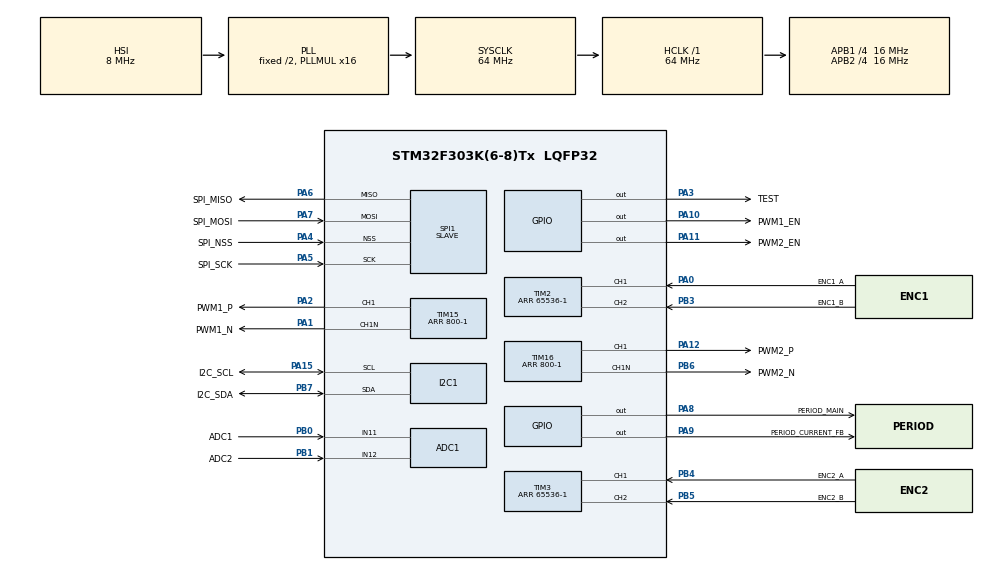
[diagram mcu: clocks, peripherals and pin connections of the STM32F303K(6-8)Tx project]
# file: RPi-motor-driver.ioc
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ADC1.Channel-1\#ChannelRegularConversion=ADC_CHANNEL_11
ADC1.Channel-2\#ChannelRegularConversion=ADC_CHANNEL_12
ADC1.ClockPrescaler=ADC_CLOCK_SYNC_PCLK_DIV4
ADC1.ContinuousConvMode=ENABLE
ADC1.DMAContinuousRequests=ENABLE
ADC1.EOCSelection=ADC_EOC_SINGLE_CONV
ADC1.EnableInjectedConversion=DISABLE
ADC1.NbrOfConversion=2
ADC1.NbrOfConversionFlag=1
ADC1.Offset-1\#ChannelRegularConversion=0
ADC1.Offset-2\#ChannelRegularConversion=0
ADC1.OffsetNumber-1\#ChannelRegularConversion=ADC_OFFSET_NONE
ADC1.OffsetNumber-2\#ChannelRegularConversion=ADC_OFFSET_NONE
ADC1.Rank-1\#ChannelRegularConversion=1
ADC1.Rank-2\#ChannelRegularConversion=2
ADC1.SamplingTime-1\#ChannelRegularConversion=ADC_SAMPLETIME_181CYCLES_5
ADC1.SamplingTime-2\#ChannelRegularConversion=ADC_SAMPLETIME_181CYCLES_5
ADC1.SequencerNbRanks=1
ADC1.SubFamily=STM32F303x8
ADC1.master=1
Dma.ADC1.0.Direction=DMA_PERIPH_TO_MEMORY
Dma.ADC1.0.Instance=DMA1_Channel1
Dma.ADC1.0.MemDataAlignment=DMA_MDATAALIGN_HALFWORD
Dma.ADC1.0.MemInc=DMA_MINC_ENABLE
Dma.ADC1.0.Mode=DMA_CIRCULAR
Dma.ADC1.0.PeriphDataAlignment=DMA_PDATAALIGN_HALFWORD
Dma.ADC1.0.PeriphInc=DMA_PINC_DISABLE
Dma.ADC1.0.Priority=DMA_PRIORITY_LOW
Dma.Request0=ADC1
Mcu.Family=STM32F3
Mcu.Name=STM32F303K(6-8)Tx
Mcu.Package=LQFP32
NVIC.DMA1_Channel1_IRQn=true\:0\:0\:false\:false\:true\:false\:true\:true
NVIC.PriorityGroup=NVIC_PRIORITYGROUP_4
NVIC.SPI1_IRQn=true\:0\:0\:false\:false\:true\:true\:true\:true
NVIC.TIM1_TRG_COM_TIM17_IRQn=true\:0\:0\:false\:false\:true\:true\:true\:true
NVIC.TIM1_UP_TIM16_IRQn=true\:15\:0\:false\:false\:true\:false\:true\:true
NVIC.TIM2_IRQn=true\:0\:0\:false\:false\:true\:true\:true\:true
NVIC.TIM3_IRQn=true\:0\:0\:false\:false\:true\:true\:true\:true
NVIC.TIM6_DAC1_IRQn=true\:0\:0\:false\:false\:true\:true\:true\:true
PA0.GPIO_Label=ENC1_A
PA0.Signal=S_TIM2_CH1_ETR
PA1.GPIO_Label=PWM1_N
PA1.Mode=PWM Generation1 CH1 CH1N
PA1.Signal=TIM15_CH1N
PA10.GPIO_Label=PWM1_EN
PA10.GPIO_PuPd=GPIO_PULLDOWN
PA10.Signal=GPIO_Output
PA11.GPIO_Label=PWM2_EN
PA11.GPIO_PuPd=GPIO_PULLDOWN
PA11.Signal=GPIO_Output
PA12.GPIO_Label=PWM2_P
PA12.Signal=S_TIM16_CH1
PA13.GPIO_Label=SWDIO
PA13.Mode=Serial_Wire
PA13.Signal=SYS_JTMS-SWDIO
PA14.GPIO_Label=SWCLK
PA14.Mode=Serial_Wire
PA14.Signal=SYS_JTCK-SWCLK
PA15.GPIO_Label=I2C_SCL
PA15.Mode=I2C
PA15.Signal=I2C1_SCL
PA2.GPIO_Label=PWM1_P
PA2.Signal=S_TIM15_CH1
PA3.GPIO_Label=TEST
PA3.GPIO_PuPd=GPIO_PULLUP
PA3.PinState=GPIO_PIN_RESET
PA3.Signal=GPIO_Output
PA4.GPIO_Label=SPI_NSS
PA4.GPIO_PuPd=GPIO_NOPULL
PA4.Mode=NSS_Signal_Hard_Input
PA4.Signal=SPI1_NSS
PA5.GPIO_Label=SPI_SCK
PA5.GPIO_PuPd=GPIO_NOPULL
PA5.Mode=Full_Duplex_Slave
PA5.Signal=SPI1_SCK
PA6.GPIO_Label=SPI_MISO
PA6.GPIO_PuPd=GPIO_NOPULL
PA6.Mode=Full_Duplex_Slave
PA6.Signal=SPI1_MISO
PA7.GPIO_Label=SPI_MOSI
PA7.GPIO_PuPd=GPIO_NOPULL
PA7.Mode=Full_Duplex_Slave
PA7.Signal=SPI1_MOSI
PA8.GPIO_Label=PERIOD_MAIN
PA8.GPIO_PuPd=GPIO_PULLUP
PA8.Signal=GPIO_Output
PA9.GPIO_Label=PERIOD_CURRENT_FB
PA9.GPIO_PuPd=GPIO_PULLUP
PA9.Signal=GPIO_Output
PB0.GPIO_Label=ADC1
PB0.Mode=IN11-Single-Ended
PB0.Signal=ADC1_IN11
PB1.GPIO_Label=ADC2
PB1.Mode=IN12-Single-Ended
PB1.Signal=ADC1_IN12
PB3.GPIO_Label=ENC1_B
PB3.Signal=S_TIM2_CH2
PB4.GPIO_Label=ENC2_A
PB4.Signal=S_TIM3_CH1
PB5.GPIO_Label=ENC2_B
PB5.Signal=S_TIM3_CH2
PB6.GPIO_Label=PWM2_N
PB6.Mode=PWM Generation1 CH1 CH1N
PB6.Signal=TIM16_CH1N
PB7.GPIO_Label=I2C_SDA
PB7.Mode=I2C
PB7.Signal=I2C1_SDA
ProjectManager.HeapSize=0x200
ProjectManager.StackSize=0x400
ProjectManager.TargetToolchain=STM32CubeIDE
RCC.AHBFreq_Value=64000000
RCC.APB1CLKDivider=RCC_HCLK_DIV4
RCC.APB1Freq_Value=16000000
RCC.APB1TimFreq_Value=32000000
RCC.APB2CLKDivider=RCC_HCLK_DIV4
RCC.APB2Freq_Value=16000000
RCC.APB2TimFreq_Value=32000000
RCC.CortexFreq_Value=8000000
RCC.Cortex_Div=SYSTICK_CLKSOURCE_HCLK_DIV8
RCC.HCLKFreq_Value=64000000
RCC.HSE_VALUE=8000000
RCC.HSI_VALUE=8000000
RCC.PLLMUL=RCC_PLL_MUL16
RCC.SYSCLKFreq_VALUE=64000000
RCC.SYSCLKSourceVirtual=RCC_SYSCLKSOURCE_PLLCLK
SH.S_TIM15_CH1.0=TIM15_CH1,PWM Generation1 CH1 CH1N
SH.S_TIM16_CH1.0=TIM16_CH1,PWM Generation1 CH1 CH1N
SH.S_TIM2_CH1_ETR.0=TIM2_CH1,Encoder_Interface
SH.S_TIM2_CH2.0=TIM2_CH2,Encoder_Interface
SH.S_TIM3_CH1.0=TIM3_CH1,Encoder_Interface
SH.S_TIM3_CH2.0=TIM3_CH2,Encoder_Interface
SPI1.DataSize=SPI_DATASIZE_8BIT
SPI1.Direction=SPI_DIRECTION_2LINES
SPI1.Mode=SPI_MODE_SLAVE
SPI1.VirtualNSS=VM_NSSHARD
SPI1.VirtualType=VM_SLAVE
TIM15.Channel-PWM\ Generation1\ CH1\ CH1N=TIM_CHANNEL_1
TIM15.DeadTime=0
TIM15.Period=800-1
TIM15.Pulse-PWM\ Generation1\ CH1\ CH1N=400
TIM16.Channel=TIM_CHANNEL_1
TIM16.ClockDivision=TIM_CLOCKDIVISION_DIV1
TIM16.Period=800-1
TIM16.Pulse=400
TIM17.Period=3200-1
TIM2.EncoderMode=TIM_ENCODERMODE_TI12
TIM2.Period=65536-1
TIM3.EncoderMode=TIM_ENCODERMODE_TI12
TIM3.Period=65536-1
TIM6.Period=32000-1
TIM6.Prescaler=0
VP_TIM16_VS_ClockSourceINT.Mode=Enable_Timer
VP_TIM17_VS_ClockSourceINT.Mode=Enable_Timer
VP_TIM6_VS_ClockSourceINT.Mode=Enable_Timer
board=custom

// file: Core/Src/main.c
/* USER CODE BEGIN Header */
/**
 ******************************************************************************
 * @file           : main.c
 * @brief          : Main program body
 ******************************************************************************
 * @attention
 *
 * Copyright (c) 2023 STMicroelectronics.
 * All rights reserved.
 *
 * This software is licensed under terms that can be found in the LICENSE file
 * in the root directory of this software component.
 * If no LICENSE file comes with this software, it is provided AS-IS.
 *
 ******************************************************************************
 */
/* USER CODE END Header */
#include "main.h"

/* USER CODE BEGIN Includes */
#include "board.h"
#include "callback.h"
/* USER CODE END Includes */

ADC_HandleTypeDef hadc1;
DMA_HandleTypeDef hdma_adc1;

I2C_HandleTypeDef hi2c1;

SPI_HandleTypeDef hspi1;

TIM_HandleTypeDef htim2;
TIM_HandleTypeDef htim3;
TIM_HandleTypeDef htim6;
TIM_HandleTypeDef htim15;
TIM_HandleTypeDef htim16;
TIM_HandleTypeDef htim17;

void SystemClock_Config(void);
static void MX_GPIO_Init(void);
static void MX_DMA_Init(void);
static void MX_ADC1_Init(void);
static void MX_I2C1_Init(void);
static void MX_SPI1_Init(void);
static void MX_TIM2_Init(void);
static void MX_TIM3_Init(void);
static void MX_TIM15_Init(void);
static void MX_TIM16_Init(void);
static void MX_TIM17_Init(void);
static void MX_TIM6_Init(void);

int main(void)
{

  /* MCU Configuration--------------------------------------------------------*/

  /* Reset of all peripherals, Initializes the Flash interface and the Systick. */
  HAL_Init();

  /* Configure the system clock */
  SystemClock_Config();

  /* Initialize all configured peripherals */
  MX_GPIO_Init();
  MX_DMA_Init();
  MX_ADC1_Init();
  MX_I2C1_Init();
  MX_SPI1_Init();
  MX_TIM2_Init();
  MX_TIM3_Init();
  MX_TIM15_Init();
  MX_TIM16_Init();
  MX_TIM17_Init();
  MX_TIM6_Init();
  /* USER CODE BEGIN 2 */
	/* State initialize */
	board_start();
  /* USER CODE END 2 */

  /* Infinite loop */
  /* USER CODE BEGIN WHILE */
	while (1) {
		/* Check main process execution period START */
		HAL_GPIO_WritePin(PERIOD_MAIN_GPIO_Port, PERIOD_MAIN_Pin, GPIO_PIN_SET);

		/* Updating state */
		board_update();

		/* Check main process execution period END */
		HAL_GPIO_WritePin(PERIOD_MAIN_GPIO_Port, PERIOD_MAIN_Pin,
				GPIO_PIN_RESET);
    /* USER CODE END WHILE */

	}
}

void SystemClock_Config(void)
{
  RCC_OscInitTypeDef RCC_OscInitStruct = {0};
  RCC_ClkInitTypeDef RCC_ClkInitStruct = {0};
  RCC_PeriphCLKInitTypeDef PeriphClkInit = {0};

  /** Initializes the RCC Oscillators according to the specified parameters
  * in the RCC_OscInitTypeDef structure.
  */
  RCC_OscInitStruct.OscillatorType = RCC_OSCILLATORTYPE_HSI;
  RCC_OscInitStruct.HSIState = RCC_HSI_ON;
  RCC_OscInitStruct.HSICalibrationValue = RCC_HSICALIBRATION_DEFAULT;
  RCC_OscInitStruct.PLL.PLLState = RCC_PLL_ON;
  RCC_OscInitStruct.PLL.PLLSource = RCC_PLLSOURCE_HSI;
  RCC_OscInitStruct.PLL.PLLMUL = RCC_PLL_MUL16;
  if (HAL_RCC_OscConfig(&RCC_OscInitStruct) != HAL_OK)
  {
    Error_Handler();
  }

  /** Initializes the CPU, AHB and APB buses clocks
  */
  RCC_ClkInitStruct.ClockType = RCC_CLOCKTYPE_HCLK|RCC_CLOCKTYPE_SYSCLK
                              |RCC_CLOCKTYPE_PCLK1|RCC_CLOCKTYPE_PCLK2;
  RCC_ClkInitStruct.SYSCLKSource = RCC_SYSCLKSOURCE_PLLCLK;
  RCC_ClkInitStruct.AHBCLKDivider = RCC_SYSCLK_DIV1;
  RCC_ClkInitStruct.APB1CLKDivider = RCC_HCLK_DIV4;
  RCC_ClkInitStruct.APB2CLKDivider = RCC_HCLK_DIV4;

  if (HAL_RCC_ClockConfig(&RCC_ClkInitStruct, FLASH_LATENCY_2) != HAL_OK)
  {
    Error_Handler();
  }
  PeriphClkInit.PeriphClockSelection = RCC_PERIPHCLK_I2C1;
  PeriphClkInit.I2c1ClockSelection = RCC_I2C1CLKSOURCE_HSI;
  if (HAL_RCCEx_PeriphCLKConfig(&PeriphClkInit) != HAL_OK)
  {
    Error_Handler();
  }
}

static void MX_ADC1_Init(void)
{

  ADC_MultiModeTypeDef multimode = {0};
  ADC_ChannelConfTypeDef sConfig = {0};

  /** Common config
  */
  hadc1.Instance = ADC1;
  hadc1.Init.ClockPrescaler = ADC_CLOCK_SYNC_PCLK_DIV4;
  hadc1.Init.Resolution = ADC_RESOLUTION_12B;
  hadc1.Init.ScanConvMode = ADC_SCAN_ENABLE;
  hadc1.Init.ContinuousConvMode = ENABLE;
  hadc1.Init.DiscontinuousConvMode = DISABLE;
  hadc1.Init.ExternalTrigConvEdge = ADC_EXTERNALTRIGCONVEDGE_NONE;
  hadc1.Init.ExternalTrigConv = ADC_SOFTWARE_START;
  hadc1.Init.DataAlign = ADC_DATAALIGN_RIGHT;
  hadc1.Init.NbrOfConversion = 2;
  hadc1.Init.DMAContinuousRequests = ENABLE;
  hadc1.Init.EOCSelection = ADC_EOC_SINGLE_CONV;
  hadc1.Init.LowPowerAutoWait = DISABLE;
  hadc1.Init.Overrun = ADC_OVR_DATA_OVERWRITTEN;
  if (HAL_ADC_Init(&hadc1) != HAL_OK)
  {
    Error_Handler();
  }

  /** Configure the ADC multi-mode
  */
  multimode.Mode = ADC_MODE_INDEPENDENT;
  if (HAL_ADCEx_MultiModeConfigChannel(&hadc1, &multimode) != HAL_OK)
  {
    Error_Handler();
  }

  /** Configure Regular Channel
  */
  sConfig.Channel = ADC_CHANNEL_11;
  sConfig.Rank = ADC_REGULAR_RANK_1;
  sConfig.SingleDiff = ADC_SINGLE_ENDED;
  sConfig.SamplingTime = ADC_SAMPLETIME_181CYCLES_5;
  sConfig.OffsetNumber = ADC_OFFSET_NONE;
  sConfig.Offset = 0;
  if (HAL_ADC_ConfigChannel(&hadc1, &sConfig) != HAL_OK)
  {
    Error_Handler();
  }

  /** Configure Regular Channel
  */
  sConfig.Channel = ADC_CHANNEL_12;
  sConfig.Rank = ADC_REGULAR_RANK_2;
  if (HAL_ADC_ConfigChannel(&hadc1, &sConfig) != HAL_OK)
  {
    Error_Handler();
  }

}

static void MX_I2C1_Init(void)
{

  hi2c1.Instance = I2C1;
  hi2c1.Init.Timing = 0x2000090E;
  hi2c1.Init.OwnAddress1 = 0;
  hi2c1.Init.AddressingMode = I2C_ADDRESSINGMODE_7BIT;
  hi2c1.Init.DualAddressMode = I2C_DUALADDRESS_DISABLE;
  hi2c1.Init.OwnAddress2 = 0;
  hi2c1.Init.OwnAddress2Masks = I2C_OA2_NOMASK;
  hi2c1.Init.GeneralCallMode = I2C_GENERALCALL_DISABLE;
  hi2c1.Init.NoStretchMode = I2C_NOSTRETCH_DISABLE;
  if (HAL_I2C_Init(&hi2c1) != HAL_OK)
  {
    Error_Handler();
  }

  /** Configure Analogue filter
  */
  if (HAL_I2CEx_ConfigAnalogFilter(&hi2c1, I2C_ANALOGFILTER_ENABLE) != HAL_OK)
  {
    Error_Handler();
  }

  /** Configure Digital filter
  */
  if (HAL_I2CEx_ConfigDigitalFilter(&hi2c1, 0) != HAL_OK)
  {
    Error_Handler();
  }

}

static void MX_SPI1_Init(void)
{

  /* SPI1 parameter configuration*/
  hspi1.Instance = SPI1;
  hspi1.Init.Mode = SPI_MODE_SLAVE;
  hspi1.Init.Direction = SPI_DIRECTION_2LINES;
  hspi1.Init.DataSize = SPI_DATASIZE_8BIT;
  hspi1.Init.CLKPolarity = SPI_POLARITY_LOW;
  hspi1.Init.CLKPhase = SPI_PHASE_1EDGE;
  hspi1.Init.NSS = SPI_NSS_HARD_INPUT;
  hspi1.Init.FirstBit = SPI_FIRSTBIT_MSB;
  hspi1.Init.TIMode = SPI_TIMODE_DISABLE;
  hspi1.Init.CRCCalculation = SPI_CRCCALCULATION_DISABLE;
  hspi1.Init.CRCPolynomial = 7;
  hspi1.Init.CRCLength = SPI_CRC_LENGTH_DATASIZE;
  hspi1.Init.NSSPMode = SPI_NSS_PULSE_DISABLE;
  if (HAL_SPI_Init(&hspi1) != HAL_OK)
  {
    Error_Handler();
  }

}

static void MX_TIM2_Init(void)
{

  TIM_Encoder_InitTypeDef sConfig = {0};
  TIM_MasterConfigTypeDef sMasterConfig = {0};

  htim2.Instance = TIM2;
  htim2.Init.Prescaler = 0;
  htim2.Init.CounterMode = TIM_COUNTERMODE_UP;
  htim2.Init.Period = 65536-1;
  htim2.Init.ClockDivision = TIM_CLOCKDIVISION_DIV1;
  htim2.Init.AutoReloadPreload = TIM_AUTORELOAD_PRELOAD_DISABLE;
  sConfig.EncoderMode = TIM_ENCODERMODE_TI12;
  sConfig.IC1Polarity = TIM_ICPOLARITY_RISING;
  sConfig.IC1Selection = TIM_ICSELECTION_DIRECTTI;
  sConfig.IC1Prescaler = TIM_ICPSC_DIV1;
  sConfig.IC1Filter = 0;
  sConfig.IC2Polarity = TIM_ICPOLARITY_RISING;
  sConfig.IC2Selection = TIM_ICSELECTION_DIRECTTI;
  sConfig.IC2Prescaler = TIM_ICPSC_DIV1;
  sConfig.IC2Filter = 0;
  if (HAL_TIM_Encoder_Init(&htim2, &sConfig) != HAL_OK)
  {
    Error_Handler();
  }
  sMasterConfig.MasterOutputTrigger = TIM_TRGO_RESET;
  sMasterConfig.MasterSlaveMode = TIM_MASTERSLAVEMODE_DISABLE;
  if (HAL_TIMEx_MasterConfigSynchronization(&htim2, &sMasterConfig) != HAL_OK)
  {
    Error_Handler();
  }

}

static void MX_TIM3_Init(void)
{

  TIM_Encoder_InitTypeDef sConfig = {0};
  TIM_MasterConfigTypeDef sMasterConfig = {0};

  htim3.Instance = TIM3;
  htim3.Init.Prescaler = 0;
  htim3.Init.CounterMode = TIM_COUNTERMODE_UP;
  htim3.Init.Period = 65536-1;
  htim3.Init.ClockDivision = TIM_CLOCKDIVISION_DIV1;
  htim3.Init.AutoReloadPreload = TIM_AUTORELOAD_PRELOAD_DISABLE;
  sConfig.EncoderMode = TIM_ENCODERMODE_TI12;
  sConfig.IC1Polarity = TIM_ICPOLARITY_RISING;
  sConfig.IC1Selection = TIM_ICSELECTION_DIRECTTI;
  sConfig.IC1Prescaler = TIM_ICPSC_DIV1;
  sConfig.IC1Filter = 0;
  sConfig.IC2Polarity = TIM_ICPOLARITY_RISING;
  sConfig.IC2Selection = TIM_ICSELECTION_DIRECTTI;
  sConfig.IC2Prescaler = TIM_ICPSC_DIV1;
  sConfig.IC2Filter = 0;
  if (HAL_TIM_Encoder_Init(&htim3, &sConfig) != HAL_OK)
  {
    Error_Handler();
  }
  sMasterConfig.MasterOutputTrigger = TIM_TRGO_RESET;
  sMasterConfig.MasterSlaveMode = TIM_MASTERSLAVEMODE_DISABLE;
  if (HAL_TIMEx_MasterConfigSynchronization(&htim3, &sMasterConfig) != HAL_OK)
  {
    Error_Handler();
  }

}

static void MX_TIM6_Init(void)
{

  TIM_MasterConfigTypeDef sMasterConfig = {0};

  htim6.Instance = TIM6;
  htim6.Init.Prescaler = 0;
  htim6.Init.CounterMode = TIM_COUNTERMODE_UP;
  htim6.Init.Period = 32000-1;
  htim6.Init.AutoReloadPreload = TIM_AUTORELOAD_PRELOAD_DISABLE;
  if (HAL_TIM_Base_Init(&htim6) != HAL_OK)
  {
    Error_Handler();
  }
  sMasterConfig.MasterOutputTrigger = TIM_TRGO_RESET;
  sMasterConfig.MasterSlaveMode = TIM_MASTERSLAVEMODE_DISABLE;
  if (HAL_TIMEx_MasterConfigSynchronization(&htim6, &sMasterConfig) != HAL_OK)
  {
    Error_Handler();
  }

}

static void MX_TIM15_Init(void)
{

  TIM_MasterConfigTypeDef sMasterConfig = {0};
  TIM_OC_InitTypeDef sConfigOC = {0};
  TIM_BreakDeadTimeConfigTypeDef sBreakDeadTimeConfig = {0};

  htim15.Instance = TIM15;
  htim15.Init.Prescaler = 0;
  htim15.Init.CounterMode = TIM_COUNTERMODE_UP;
  htim15.Init.Period = 800-1;
  htim15.Init.ClockDivision = TIM_CLOCKDIVISION_DIV1;
  htim15.Init.RepetitionCounter = 0;
  htim15.Init.AutoReloadPreload = TIM_AUTORELOAD_PRELOAD_DISABLE;
  if (HAL_TIM_PWM_Init(&htim15) != HAL_OK)
  {
    Error_Handler();
  }
  sMasterConfig.MasterOutputTrigger = TIM_TRGO_RESET;
  sMasterConfig.MasterSlaveMode = TIM_MASTERSLAVEMODE_DISABLE;
  if (HAL_TIMEx_MasterConfigSynchronization(&htim15, &sMasterConfig) != HAL_OK)
  {
    Error_Handler();
  }
  sConfigOC.OCMode = TIM_OCMODE_PWM1;
  sConfigOC.Pulse = 400;
  sConfigOC.OCPolarity = TIM_OCPOLARITY_HIGH;
  sConfigOC.OCNPolarity = TIM_OCNPOLARITY_HIGH;
  sConfigOC.OCFastMode = TIM_OCFAST_DISABLE;
  sConfigOC.OCIdleState = TIM_OCIDLESTATE_RESET;
  sConfigOC.OCNIdleState = TIM_OCNIDLESTATE_RESET;
  if (HAL_TIM_PWM_ConfigChannel(&htim15, &sConfigOC, TIM_CHANNEL_1) != HAL_OK)
  {
    Error_Handler();
  }
  sBreakDeadTimeConfig.OffStateRunMode = TIM_OSSR_DISABLE;
  sBreakDeadTimeConfig.OffStateIDLEMode = TIM_OSSI_DISABLE;
  sBreakDeadTimeConfig.LockLevel = TIM_LOCKLEVEL_OFF;
  sBreakDeadTimeConfig.DeadTime = 0;
  sBreakDeadTimeConfig.BreakState = TIM_BREAK_DISABLE;
  sBreakDeadTimeConfig.BreakPolarity = TIM_BREAKPOLARITY_HIGH;
  sBreakDeadTimeConfig.BreakFilter = 0;
  sBreakDeadTimeConfig.AutomaticOutput = TIM_AUTOMATICOUTPUT_DISABLE;
  if (HAL_TIMEx_ConfigBreakDeadTime(&htim15, &sBreakDeadTimeConfig) != HAL_OK)
  {
    Error_Handler();
  }
  HAL_TIM_MspPostInit(&htim15);

}

static void MX_TIM16_Init(void)
{

  TIM_OC_InitTypeDef sConfigOC = {0};
  TIM_BreakDeadTimeConfigTypeDef sBreakDeadTimeConfig = {0};

  htim16.Instance = TIM16;
  htim16.Init.Prescaler = 0;
  htim16.Init.CounterMode = TIM_COUNTERMODE_UP;
  htim16.Init.Period = 800-1;
  htim16.Init.ClockDivision = TIM_CLOCKDIVISION_DIV1;
  htim16.Init.RepetitionCounter = 0;
  htim16.Init.AutoReloadPreload = TIM_AUTORELOAD_PRELOAD_DISABLE;
  if (HAL_TIM_Base_Init(&htim16) != HAL_OK)
  {
    Error_Handler();
  }
  if (HAL_TIM_PWM_Init(&htim16) != HAL_OK)
  {
    Error_Handler();
  }
  sConfigOC.OCMode = TIM_OCMODE_PWM1;
  sConfigOC.Pulse = 400;
  sConfigOC.OCPolarity = TIM_OCPOLARITY_HIGH;
  sConfigOC.OCNPolarity = TIM_OCNPOLARITY_HIGH;
  sConfigOC.OCFastMode = TIM_OCFAST_DISABLE;
  sConfigOC.OCIdleState = TIM_OCIDLESTATE_RESET;
  sConfigOC.OCNIdleState = TIM_OCNIDLESTATE_RESET;
  if (HAL_TIM_PWM_ConfigChannel(&htim16, &sConfigOC, TIM_CHANNEL_1) != HAL_OK)
  {
    Error_Handler();
  }
  sBreakDeadTimeConfig.OffStateRunMode = TIM_OSSR_DISABLE;
  sBreakDeadTimeConfig.OffStateIDLEMode = TIM_OSSI_DISABLE;
  sBreakDeadTimeConfig.LockLevel = TIM_LOCKLEVEL_OFF;
  sBreakDeadTimeConfig.DeadTime = 0;
  sBreakDeadTimeConfig.BreakState = TIM_BREAK_DISABLE;
  sBreakDeadTimeConfig.BreakPolarity = TIM_BREAKPOLARITY_HIGH;
  sBreakDeadTimeConfig.BreakFilter = 0;
  sBreakDeadTimeConfig.AutomaticOutput = TIM_AUTOMATICOUTPUT_DISABLE;
  if (HAL_TIMEx_ConfigBreakDeadTime(&htim16, &sBreakDeadTimeConfig) != HAL_OK)
  {
    Error_Handler();
  }
  HAL_TIM_MspPostInit(&htim16);

}

static void MX_TIM17_Init(void)
{

  htim17.Instance = TIM17;
  htim17.Init.Prescaler = 0;
  htim17.Init.CounterMode = TIM_COUNTERMODE_UP;
  htim17.Init.Period = 3200-1;
  htim17.Init.ClockDivision = TIM_CLOCKDIVISION_DIV1;
  htim17.Init.RepetitionCounter = 0;
  htim17.Init.AutoReloadPreload = TIM_AUTORELOAD_PRELOAD_DISABLE;
  if (HAL_TIM_Base_Init(&htim17) != HAL_OK)
  {
    Error_Handler();
  }

}

static void MX_DMA_Init(void)
{

  /* DMA controller clock enable */
  __HAL_RCC_DMA1_CLK_ENABLE();

  /* DMA interrupt init */
  /* DMA1_Channel1_IRQn interrupt configuration */
  HAL_NVIC_SetPriority(DMA1_Channel1_IRQn, 0, 0);
  HAL_NVIC_EnableIRQ(DMA1_Channel1_IRQn);

}

static void MX_GPIO_Init(void)
{
  GPIO_InitTypeDef GPIO_InitStruct = {0};

  /* GPIO Ports Clock Enable */
  __HAL_RCC_GPIOA_CLK_ENABLE();
  __HAL_RCC_GPIOB_CLK_ENABLE();

  /*Configure GPIO pin Output Level */
  HAL_GPIO_WritePin(GPIOA, TEST_Pin|PERIOD_MAIN_Pin|PERIOD_CURRENT_FB_Pin|PWM1_EN_Pin
                          |PWM2_EN_Pin, GPIO_PIN_RESET);

  /*Configure GPIO pins : TEST_Pin PERIOD_MAIN_Pin PERIOD_CURRENT_FB_Pin */
  GPIO_InitStruct.Pin = TEST_Pin|PERIOD_MAIN_Pin|PERIOD_CURRENT_FB_Pin;
  GPIO_InitStruct.Mode = GPIO_MODE_OUTPUT_PP;
  GPIO_InitStruct.Pull = GPIO_PULLUP;
  GPIO_InitStruct.Speed = GPIO_SPEED_FREQ_LOW;
  HAL_GPIO_Init(GPIOA, &GPIO_InitStruct);

  /*Configure GPIO pins : PWM1_EN_Pin PWM2_EN_Pin */
  GPIO_InitStruct.Pin = PWM1_EN_Pin|PWM2_EN_Pin;
  GPIO_InitStruct.Mode = GPIO_MODE_OUTPUT_PP;
  GPIO_InitStruct.Pull = GPIO_PULLDOWN;
  GPIO_InitStruct.Speed = GPIO_SPEED_FREQ_LOW;
  HAL_GPIO_Init(GPIOA, &GPIO_InitStruct);

}

void Error_Handler(void)
{
	__disable_irq();
	while (1) {
	}
}
